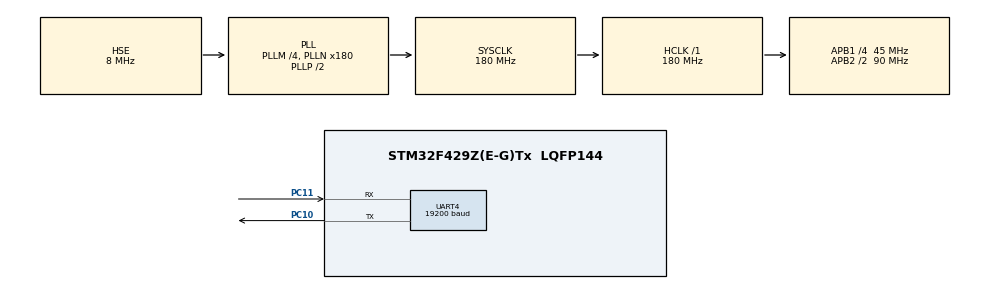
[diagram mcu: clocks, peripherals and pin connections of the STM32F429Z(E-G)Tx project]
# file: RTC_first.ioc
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Mcu.Family=STM32F4
Mcu.Name=STM32F429Z(E-G)Tx
Mcu.Package=LQFP144
NVIC.PriorityGroup=NVIC_PRIORITYGROUP_4
NVIC.RTC_Alarm_IRQn=true\:0\:0\:false\:false\:true\:true\:true
PA13.Mode=Serial_Wire
PA13.Signal=SYS_JTMS-SWDIO
PA14.Mode=Serial_Wire
PA14.Signal=SYS_JTCK-SWCLK
PC10.Mode=Asynchronous
PC10.Signal=UART4_TX
PC11.Mode=Asynchronous
PC11.Signal=UART4_RX
PC14/OSC32_IN.Mode=LSE-External-Oscillator
PC14/OSC32_IN.Signal=RCC_OSC32_IN
PC15/OSC32_OUT.Mode=LSE-External-Oscillator
PC15/OSC32_OUT.Signal=RCC_OSC32_OUT
PH0/OSC_IN.Mode=HSE-External-Oscillator
PH0/OSC_IN.Signal=RCC_OSC_IN
PH1/OSC_OUT.Mode=HSE-External-Oscillator
PH1/OSC_OUT.Signal=RCC_OSC_OUT
ProjectManager.HeapSize=0x200
ProjectManager.StackSize=0x400
ProjectManager.TargetToolchain=MDK-ARM V5.27
RCC.48MHZClocksFreq_Value=90000000
RCC.AHBFreq_Value=180000000
RCC.APB1CLKDivider=RCC_HCLK_DIV4
RCC.APB1Freq_Value=45000000
RCC.APB1TimFreq_Value=90000000
RCC.APB2CLKDivider=RCC_HCLK_DIV2
RCC.APB2Freq_Value=90000000
RCC.APB2TimFreq_Value=180000000
RCC.CortexFreq_Value=180000000
RCC.HCLKFreq_Value=180000000
RCC.HSE_VALUE=8000000
RCC.HSI_VALUE=16000000
RCC.PLLM=4
RCC.PLLN=180
RCC.PLLSourceVirtual=RCC_PLLSOURCE_HSE
RCC.RCC_RTC_Clock_Source=RCC_RTCCLKSOURCE_LSE
RCC.RCC_RTC_Clock_SourceVirtual=RCC_RTCCLKSOURCE_LSE
RCC.SYSCLKFreq_VALUE=180000000
RCC.SYSCLKSource=RCC_SYSCLKSOURCE_PLLCLK
RCC.VCOOutputFreq_Value=360000000
RTC.Alarm=RTC_ALARM_A
RTC.Date=29
RTC.Format=RTC_FORMAT_BIN
RTC.Hours=INITIAL_HOUR
RTC.Minutes=INITIAL_MINUTE
RTC.Month=RTC_MONTH_JUNE
RTC.Seconds=INITIAL_SECOND
RTC.Seconds_A=10
RTC.Year=20
UART4.BaudRate=19200
UART4.VirtualMode=Asynchronous
VP_RTC_VS_RTC_Activate.Mode=RTC_Enabled
VP_RTC_VS_RTC_Alarm_A_Intern.Mode=Alarm A
VP_RTC_VS_RTC_Calendar.Mode=RTC_Calendar
board=custom

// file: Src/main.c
/* USER CODE BEGIN Header */
/**
  ******************************************************************************
  * @file           : main.c
  * @brief          : Main program body
  ******************************************************************************
  * @attention
  *
  * <h2><center>&copy; Copyright (c) 2020 STMicroelectronics.
  * All rights reserved.</center></h2>
  *
  * This software component is licensed by ST under BSD 3-Clause license,
  * the "License"; You may not use this file except in compliance with the
  * License. You may obtain a copy of the License at:
  *                        opensource.org/licenses/BSD-3-Clause
  *
  ******************************************************************************
  */
/* USER CODE END Header */

#include "main.h"

/* USER CODE BEGIN PD */
#define  INITIAL_HOUR		14
#define  INITIAL_MINUTE	45
#define  INITIAL_SECOND	3
/* USER CODE END PD */

RTC_HandleTypeDef hrtc;

UART_HandleTypeDef huart4;

/* USER CODE BEGIN PV */
RTC_TimeTypeDef time_struct		 ;
uint8_t 				second 			= 0;
uint8_t 				minute 			= 0;
uint8_t 				hour   			= 0;
int     				debugVar 		= 0;
/* USER CODE END PV */

void SystemClock_Config(void);
static void MX_GPIO_Init(void);
static void MX_RTC_Init(void);
static void MX_UART4_Init(void);

int main(void)
{

  /* MCU Configuration--------------------------------------------------------*/

  /* Reset of all peripherals, Initializes the Flash interface and the Systick. */
  HAL_Init();

  /* Configure the system clock */
  SystemClock_Config();

  /* Initialize all configured peripherals */
  MX_GPIO_Init();
  MX_RTC_Init();
  MX_UART4_Init();

  /* Infinite loop */
  while (1)
  {

    /* USER CODE BEGIN 3 */
		HAL_RTC_GetTime(&hrtc, &time_struct, RTC_FORMAT_BIN);
		second = time_struct.Seconds;
		minute = time_struct.Minutes;
		hour   = time_struct.Hours  ;
		debugVar++;
		HAL_Delay(500);
  }
  /* USER CODE END 3 */
}

void SystemClock_Config(void)
{
  RCC_OscInitTypeDef RCC_OscInitStruct = {0};
  RCC_ClkInitTypeDef RCC_ClkInitStruct = {0};
  RCC_PeriphCLKInitTypeDef PeriphClkInitStruct = {0};

  /** Configure the main internal regulator output voltage
  */
  __HAL_RCC_PWR_CLK_ENABLE();
  __HAL_PWR_VOLTAGESCALING_CONFIG(PWR_REGULATOR_VOLTAGE_SCALE1);
  /** Initializes the CPU, AHB and APB busses clocks
  */
  RCC_OscInitStruct.OscillatorType = RCC_OSCILLATORTYPE_HSE|RCC_OSCILLATORTYPE_LSE;
  RCC_OscInitStruct.HSEState = RCC_HSE_ON;
  RCC_OscInitStruct.LSEState = RCC_LSE_ON;
  RCC_OscInitStruct.PLL.PLLState = RCC_PLL_ON;
  RCC_OscInitStruct.PLL.PLLSource = RCC_PLLSOURCE_HSE;
  RCC_OscInitStruct.PLL.PLLM = 4;
  RCC_OscInitStruct.PLL.PLLN = 180;
  RCC_OscInitStruct.PLL.PLLP = RCC_PLLP_DIV2;
  RCC_OscInitStruct.PLL.PLLQ = 4;
  if (HAL_RCC_OscConfig(&RCC_OscInitStruct) != HAL_OK)
  {
    Error_Handler();
  }
  /** Activate the Over-Drive mode
  */
  if (HAL_PWREx_EnableOverDrive() != HAL_OK)
  {
    Error_Handler();
  }
  /** Initializes the CPU, AHB and APB busses clocks
  */
  RCC_ClkInitStruct.ClockType = RCC_CLOCKTYPE_HCLK|RCC_CLOCKTYPE_SYSCLK
                              |RCC_CLOCKTYPE_PCLK1|RCC_CLOCKTYPE_PCLK2;
  RCC_ClkInitStruct.SYSCLKSource = RCC_SYSCLKSOURCE_PLLCLK;
  RCC_ClkInitStruct.AHBCLKDivider = RCC_SYSCLK_DIV1;
  RCC_ClkInitStruct.APB1CLKDivider = RCC_HCLK_DIV4;
  RCC_ClkInitStruct.APB2CLKDivider = RCC_HCLK_DIV2;

  if (HAL_RCC_ClockConfig(&RCC_ClkInitStruct, FLASH_LATENCY_5) != HAL_OK)
  {
    Error_Handler();
  }
  PeriphClkInitStruct.PeriphClockSelection = RCC_PERIPHCLK_RTC;
  PeriphClkInitStruct.RTCClockSelection = RCC_RTCCLKSOURCE_LSE;
  if (HAL_RCCEx_PeriphCLKConfig(&PeriphClkInitStruct) != HAL_OK)
  {
    Error_Handler();
  }
}

static void MX_RTC_Init(void)
{

  RTC_TimeTypeDef sTime = {0};
  RTC_DateTypeDef sDate = {0};
  RTC_AlarmTypeDef sAlarm = {0};

  /** Initialize RTC Only
  */
  hrtc.Instance = RTC;
  hrtc.Init.HourFormat = RTC_HOURFORMAT_24;
  hrtc.Init.AsynchPrediv = 127;
  hrtc.Init.SynchPrediv = 255;
  hrtc.Init.OutPut = RTC_OUTPUT_DISABLE;
  hrtc.Init.OutPutPolarity = RTC_OUTPUT_POLARITY_HIGH;
  hrtc.Init.OutPutType = RTC_OUTPUT_TYPE_OPENDRAIN;
  if (HAL_RTC_Init(&hrtc) != HAL_OK)
  {
    Error_Handler();
  }

  /** Initialize RTC and set the Time and Date
  */
  sTime.Hours = INITIAL_HOUR;
  sTime.Minutes = INITIAL_MINUTE;
  sTime.Seconds = INITIAL_SECOND;
  sTime.DayLightSaving = RTC_DAYLIGHTSAVING_NONE;
  sTime.StoreOperation = RTC_STOREOPERATION_RESET;
  if (HAL_RTC_SetTime(&hrtc, &sTime, RTC_FORMAT_BIN) != HAL_OK)
  {
    Error_Handler();
  }
  sDate.WeekDay = RTC_WEEKDAY_MONDAY;
  sDate.Month = RTC_MONTH_JUNE;
  sDate.Date = 29;
  sDate.Year = 20;

  if (HAL_RTC_SetDate(&hrtc, &sDate, RTC_FORMAT_BIN) != HAL_OK)
  {
    Error_Handler();
  }
  /** Enable the Alarm A
  */
  sAlarm.AlarmTime.Hours = 0;
  sAlarm.AlarmTime.Minutes = 0;
  sAlarm.AlarmTime.Seconds = 10;
  sAlarm.AlarmTime.SubSeconds = 0;
  sAlarm.AlarmTime.DayLightSaving = RTC_DAYLIGHTSAVING_NONE;
  sAlarm.AlarmTime.StoreOperation = RTC_STOREOPERATION_RESET;
  sAlarm.AlarmMask = RTC_ALARMMASK_NONE;
  sAlarm.AlarmSubSecondMask = RTC_ALARMSUBSECONDMASK_ALL;
  sAlarm.AlarmDateWeekDaySel = RTC_ALARMDATEWEEKDAYSEL_DATE;
  sAlarm.AlarmDateWeekDay = 1;
  sAlarm.Alarm = RTC_ALARM_A;
  if (HAL_RTC_SetAlarm_IT(&hrtc, &sAlarm, RTC_FORMAT_BIN) != HAL_OK)
  {
    Error_Handler();
  }

}

static void MX_UART4_Init(void)
{

  huart4.Instance = UART4;
  huart4.Init.BaudRate = 19200;
  huart4.Init.WordLength = UART_WORDLENGTH_8B;
  huart4.Init.StopBits = UART_STOPBITS_1;
  huart4.Init.Parity = UART_PARITY_NONE;
  huart4.Init.Mode = UART_MODE_TX_RX;
  huart4.Init.HwFlowCtl = UART_HWCONTROL_NONE;
  huart4.Init.OverSampling = UART_OVERSAMPLING_16;
  if (HAL_UART_Init(&huart4) != HAL_OK)
  {
    Error_Handler();
  }

}

static void MX_GPIO_Init(void)
{

  /* GPIO Ports Clock Enable */
  __HAL_RCC_GPIOC_CLK_ENABLE();
  __HAL_RCC_GPIOH_CLK_ENABLE();
  __HAL_RCC_GPIOA_CLK_ENABLE();

}

void Error_Handler(void)
{
}

/************************ (C) COPYRIGHT STMicroelectronics *****END OF FILE****/
